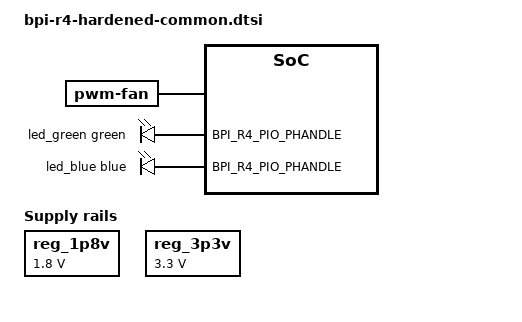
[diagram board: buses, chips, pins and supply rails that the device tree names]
// SPDX-License-Identifier: GPL-2.0-only OR MIT
/*
 * Common peripherals shared by the Banana Pi R4 hardened device trees.
 *
 * The PWM and GPIO controllers are provided through simple macros so the
 * include can be reused both from the board level DTS (which has convenient
 * labels like &pwm) and from the standalone board fragment where only the
 * absolute paths are available.  Callers should define BPI_R4_PWM_PHANDLE
 * and BPI_R4_PIO_PHANDLE before including this file.  Reasonable defaults
 * are provided when the macros are not set so that the include is resilient
 * against future refactors.
 */

#ifndef BPI_R4_PWM_PHANDLE
#define BPI_R4_PWM_PHANDLE &pwm
#endif

#ifndef BPI_R4_PIO_PHANDLE
#define BPI_R4_PIO_PHANDLE &pio
#endif

/ {
	chosen {
		stdout-path = "serial0:115200n8";
	};

	fan: pwm-fan {
		compatible = "pwm-fan";
		cooling-levels = <0 80 128 255>;
		#cooling-cells = <2>;
		pwms = <BPI_R4_PWM_PHANDLE 0 50000>;
		status = "okay";
	};

	gpio-leds {
		compatible = "gpio-leds";

		led_green: led-green {
			function = LED_FUNCTION_STATUS;
			color = <LED_COLOR_ID_GREEN>;
			gpios = <BPI_R4_PIO_PHANDLE 79 GPIO_ACTIVE_HIGH>;
			default-state = "on";
		};

		led_blue: led-blue {
			function = LED_FUNCTION_WPS;
			color = <LED_COLOR_ID_BLUE>;
			gpios = <BPI_R4_PIO_PHANDLE 63 GPIO_ACTIVE_HIGH>;
			default-state = "off";
		};
	};

	reg_1p8v: regulator-1p8v {
		compatible = "regulator-fixed";
		regulator-name = "fixed-1.8V";
		regulator-min-microvolt = <1800000>;
		regulator-max-microvolt = <1800000>;
		regulator-boot-on;
		regulator-always-on;
	};

	reg_3p3v: regulator-3p3v {
		compatible = "regulator-fixed";
		regulator-name = "fixed-3.3V";
		regulator-min-microvolt = <3300000>;
		regulator-max-microvolt = <3300000>;
		regulator-boot-on;
		regulator-always-on;
	};
};

#undef BPI_R4_PWM_PHANDLE
#undef BPI_R4_PIO_PHANDLE
